# AT91SAM9G10 register map
Vendor: Atmel; File version: 20130207
CPU: 
Registers are 32-bit, read-write, no defined reset value unless marked. A register's access mark holds for its fields unless they carry their own. Offsets are from the block's base; [hi:lo] are bit positions; {n}, {i} and the like mark numbered series.

## SMC — Static Memory Controller
Base 0xFFFFEC00; register names take the prefix SMC_
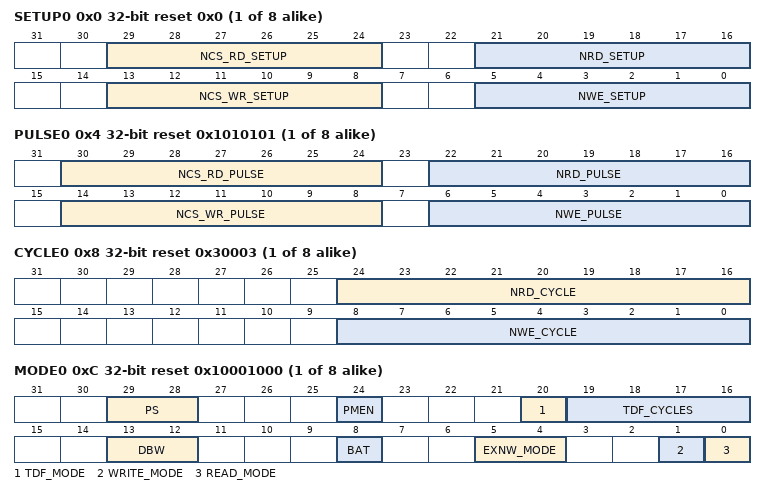
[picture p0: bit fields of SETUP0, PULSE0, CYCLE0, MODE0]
{0x0+0x10*i} SETUP{i} reset 0x0 (i=0..7) — SMC Setup Register (CS_number = {i})
  [29:24] NCS_RD_SETUP — NCS Setup Length in READ Access
  [21:16] NRD_SETUP — NRD Setup Length
  [13:8] NCS_WR_SETUP — NCS Setup Length in WRITE Access
  [5:0] NWE_SETUP — NWE Setup Length
{0x4+0x10*i} PULSE{i} reset 0x1010101 (i=0..7) — SMC Pulse Register (CS_number = {i})
  [30:24] NCS_RD_PULSE — NCS Pulse Length in READ Access
  [22:16] NRD_PULSE — NRD Pulse Length
  [14:8] NCS_WR_PULSE — NCS Pulse Length in WRITE Access
  [6:0] NWE_PULSE — NWE Pulse Length
{0x8+0x10*i} CYCLE{i} reset 0x30003 (i=0..7) — SMC Cycle Register (CS_number = {i})
  [24:16] NRD_CYCLE — Total Read Cycle Length
  [8:0] NWE_CYCLE — Total Write Cycle Length
{0xC+0x10*i} MODE{i} reset 0x10001000 (i=0..7) — SMC Mode Register (CS_number = {i})
  [29:28] PS — Page Size
  [24] PMEN — Page Mode Enabled
  [20] TDF_MODE — TDF Optimization
  [19:16] TDF_CYCLES — Data Float Time
  [13:12] DBW — Data Bus Width
  [8] BAT — Byte Access Type
  [5:4] EXNW_MODE — NWAIT Mode
  [1] WRITE_MODE
  [0] READ_MODE

## MATRIX — AHB Bus Matrix
Base 0xFFFFEE00
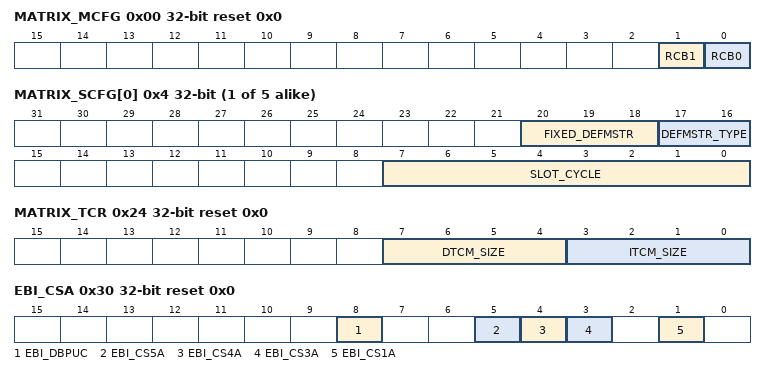
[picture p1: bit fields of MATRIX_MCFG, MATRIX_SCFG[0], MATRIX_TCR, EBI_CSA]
0x00 MATRIX_MCFG wo reset 0x0 — Master Configuration Register
  [1] RCB1 — Remap Command Bit for AHB Master 1
  [0] RCB0 — Remap Command Bit for AHB Master 0
{0x4+4i} MATRIX_SCFG[{i}] (i=0..4) — Slave Configuration Register
  [20:18] FIXED_DEFMSTR — Fixed Index of Default Master
  [17:16] DEFMSTR_TYPE
  [7:0] SLOT_CYCLE — Maximum Number of Allowed Cycles for a Burst
0x24 MATRIX_TCR reset 0x0 — MATRIX TCM Configuration Register
  [7:4] DTCM_SIZE — Size of DTCM enabled memory block
  [3:0] ITCM_SIZE — Size of ITCM enabled memory block
0x30 EBI_CSA reset 0x0 — EBI Chip Select Assignment Register
  [8] EBI_DBPUC — EBI Data Bus Pull-Up Configuration
  [5] EBI_CS5A — EBI Chip Select 5 Assignment
  [4] EBI_CS4A — EBI Chip Select 4 Assignment
  [3] EBI_CS3A — EBI Chip Select 3 Assignment
  [1] EBI_CS1A — EBI Chip Select 1 Assignment
0x34 USB_PUCR reset 0x0 — USB Pad Pull-up Control Register
  [30] UDP_PUP_ON — UDP Pad Pull-up Enable

## AIC — Advanced Interrupt Controller
Base 0xFFFFF000; register names take the prefix AIC_
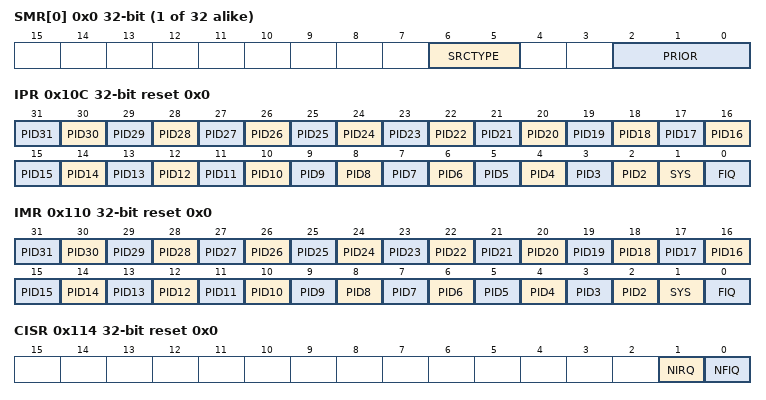
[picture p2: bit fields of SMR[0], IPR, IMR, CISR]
{0x0+4i} SMR[{i}] (i=0..31) — Source Mode Register
  [6:5] SRCTYPE — Interrupt Source Type
  [2:0] PRIOR — Priority Level
{0x80+4i} SVR[{i}] (i=0..31) — Source Vector Register
  [31:0] VECTOR — Source Vector
0x100 IVR ro reset 0x0 — Interrupt Vector Register
  [31:0] IRQV
0x104 FVR ro reset 0x0 — FIQ Interrupt Vector Register
  [31:0] FIQV — FIQ Vector Register
0x108 ISR ro reset 0x0 — Interrupt Status Register
  [4:0] IRQID — Current Interrupt Identifier
0x10C IPR ro reset 0x0 — Interrupt Pending Register
  [n] PID{n} (n=2..31) — Interrupt Pending
  [1] SYS — Interrupt Pending
  [0] FIQ — Interrupt Pending
0x110 IMR ro reset 0x0 — Interrupt Mask Register
  [n] PID{n} (n=2..31) — Interrupt Mask
  [1] SYS — Interrupt Mask
  [0] FIQ — Interrupt Mask
0x114 CISR ro reset 0x0 — Core Interrupt Status Register
  [1] NIRQ — NIRQ Status
  [0] NFIQ — NFIQ Status
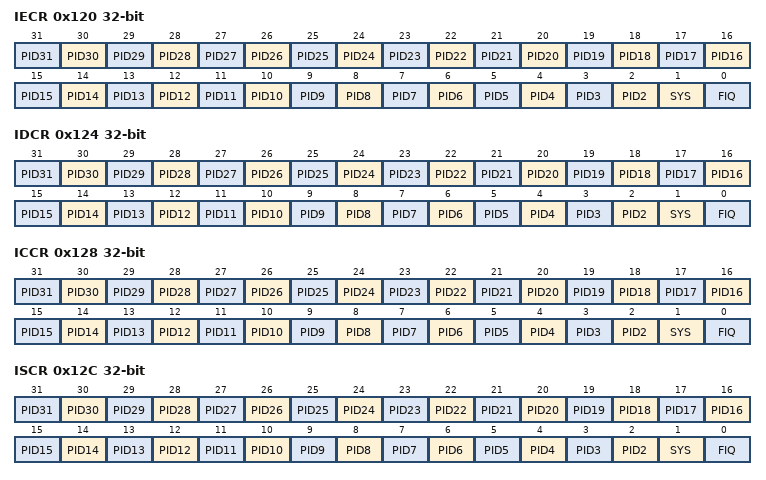
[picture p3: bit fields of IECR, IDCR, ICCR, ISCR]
0x120 IECR wo — Interrupt Enable Command Register
  [n] PID{n} (n=2..31) — Interrupt Enable
  [1] SYS — Interrupt Enable
  [0] FIQ — Interrupt Enable
0x124 IDCR wo — Interrupt Disable Command Register
  [n] PID{n} (n=2..31) — Interrupt Disable
  [1] SYS — Interrupt Disable
  [0] FIQ — Interrupt Disable
0x128 ICCR wo — Interrupt Clear Command Register
  [n] PID{n} (n=2..31) — Interrupt Clear
  [1] SYS — Interrupt Clear
  [0] FIQ — Interrupt Clear
0x12C ISCR wo — Interrupt Set Command Register
  [n] PID{n} (n=2..31) — Interrupt Set
  [1] SYS — Interrupt Set
  [0] FIQ — Interrupt Set
0x130 EOICR wo — End of Interrupt Command Register
0x134 SPU reset 0x0 — Spurious Interrupt Vector Register
  [31:0] SIVR
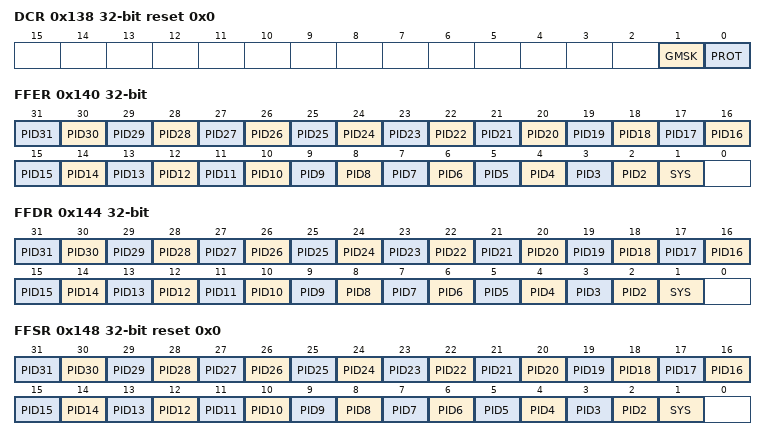
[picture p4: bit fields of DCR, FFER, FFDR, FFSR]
0x138 DCR reset 0x0 — Debug Control Register
  [1] GMSK — General Mask
  [0] PROT — Protection Mode
0x140 FFER wo — Fast Forcing Enable Register
  [n] PID{n} (n=2..31) — Fast Forcing Enable
  [1] SYS — Fast Forcing Enable
0x144 FFDR wo — Fast Forcing Disable Register
  [n] PID{n} (n=2..31) — Fast Forcing Disable
  [1] SYS — Fast Forcing Disable
0x148 FFSR ro reset 0x0 — Fast Forcing Status Register
  [n] PID{n} (n=2..31) — Fast Forcing Status
  [1] SYS — Fast Forcing Status
